# STM32N657 register map
File version: 1.0
CPU: CM55 r0p1, little endian, no MPU, FPU, vendor SysTick, 8 interrupt priority bits
Registers are 32-bit, read-write, reset 0x0 unless marked. A register's access mark holds for its fields unless they carry their own. Offsets are from the block's base; [hi:lo] are bit positions; {n}, {i} and the like mark numbered series; 'fields as' and 'values as' point back to an identical list.

## SYSCFG — System configuration controller
Base 0x46008000
Same registers: SYSCFG_S 0x56008000
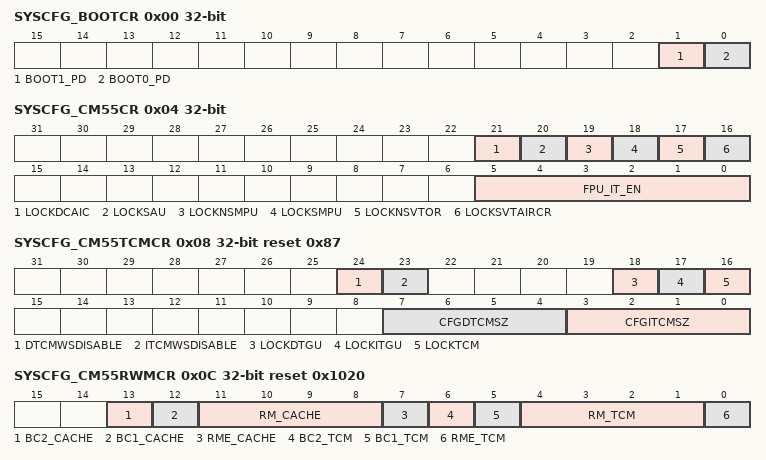
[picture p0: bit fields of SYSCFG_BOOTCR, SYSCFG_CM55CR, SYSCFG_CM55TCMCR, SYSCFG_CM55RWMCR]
0x00 SYSCFG_BOOTCR — SYSCFG boot pin control register
  [1] BOOT1_PD — BOOT1 pin pull-down disable
    0=Pull-down enabled. The BOOT1 pin can be left open and takes a value of 0 if open.; 1=Pull-down disabled. The BOOT1 pin must not be left open.
  [0] BOOT0_PD — BOOT0 pin pull-down disable
    0=Pull-down enabled. The BOOT0 pin can be left open and takes a value of 0 if open.; 1=Pull-down disabled. The BOOT0 pin must not be left open.
0x04 SYSCFG_CM55CR — SYSCFG Cortex-M55 control register
  [21] LOCKDCAIC — Disable access to the instruction cache direct cache access registers DCAICLR and DCAICRR.
  [20] LOCKSAU — Prevent changes to secure SAU memory regions already programmed.
  [19] LOCKNSMPU — Prevent changes to non-secure MPU memory regions already programmed.
  [18] LOCKSMPU — Prevent changes to programmed secure MPU memory regions.
  [17] LOCKNSVTOR — Prevent changes to the non-secure vector table base address.
  [16] LOCKSVTAIRCR — Prevent changes to:
  [5:0] FPU_IT_EN — Enable FPU exception
0x08 SYSCFG_CM55TCMCR reset 0x87 — SYSCFG Cortex-M55 TCM control register
  [24] DTCMWSDISABLE — Disable wait-state applied by default on extended DTCM memory.
  [23] ITCMWSDISABLE — Disable wait-state applied by default on extended ITCM memory.
  [18] LOCKDTGU — Disable writes to registers associated with the DTCM interface security gating.
  [17] LOCKITGU — Disable writes to registers associated with the ITCM interface security gating.
  [16] LOCKTCM — Disable writes to registers associated with the TCM region
  [7:4] CFGDTCMSZ — Select DTCM memory size
    8=128 Kbytes (default value); 9=256 Kbytes
  [3:0] CFGITCMSZ — Select ITCM memory size
    7=64 KB (default value); 8=128 Kbytes; 9=256 Kbytes
0x0C SYSCFG_CM55RWMCR reset 0x1020 — SYSCFG Cortex-CM55 memory RW margin register
  [13] BC2_CACHE — Biasing level adjust input recommended for Vnom + 10%
  [12] BC1_CACHE — Biasing level adjust input recommended for Vnom.
  [11:8] RM_CACHE — External read/write (RW) margin inputs for caches memories
  [7] RME_CACHE — RW margin enable input for caches memories
    0=Default RW margin settings; 1=Use external pin RW margin setting
  [6] BC2_TCM — Biasing level adjust input recommended for Vnom + 10%
  [5] BC1_TCM — Biasing level adjust input recommended for Vnom
  [4:1] RM_TCM — External RW margin inputs for TCM memories
  [0] RME_TCM — RW margin enable input for TCM memories
    values as RME_CACHE
0x10 SYSCFG_INITSVTORCR reset 0x18000000 — SYSCFG Cortex-M55 SVTOR control register
  [31:7] SVTOR_ADDR — Secure vector table base address
0x14 SYSCFG_INITNSVTORCR reset 0x8000000 — SYSCFG Cortex-M55 NSVTOR control register
  [31:7] NSVTOR_ADDR — Non-secure vector table base address
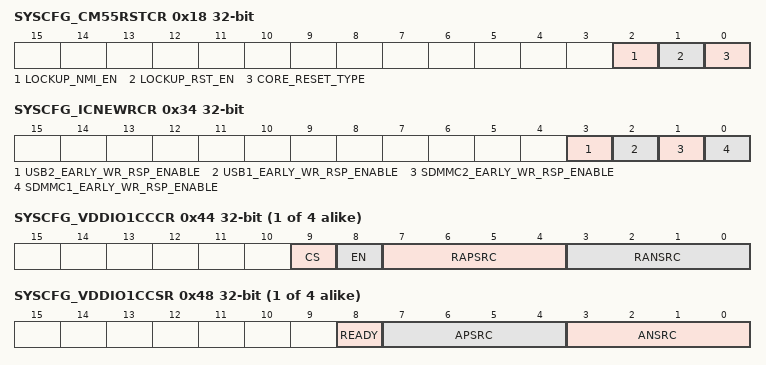
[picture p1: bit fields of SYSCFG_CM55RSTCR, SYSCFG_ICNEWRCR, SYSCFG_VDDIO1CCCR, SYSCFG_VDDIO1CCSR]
0x18 SYSCFG_CM55RSTCR — SYSCFG Cortex-M55 reset type control register
  [2] LOCKUP_NMI_EN — Select action to perform on a lockup state on the core
    0=Lockup state must be recovered from NVIC interrupt (default value); 1=Lockup generates a NMI on the core
  [1] LOCKUP_RST_EN — Select action to perform on a lockup state on the core
    0=Lockup state shall be recovered from interrupt (default value); 1=Lockup requests a warm reset to the RCC
  [0] CORE_RESET_TYPE — Select reset to apply on core upon SYSRESETREQ
    0=Warm reset (default value); 1=Power-on reset
0x1C SYSCFG_CM55PAHBWPR — SYSCFG Cortex-M55 P-AHB write posting control register
  [0] PAHB_ERROR_ACK — Error capture in write posting buffer
    0=Error capture; 1=Clean error
0x20 SYSCFG_VENCRAMCR — SYSCFG VENCRAM control register
  [0] VENCRAM_EN — VENCRAM allocation VENC if active, or to system (if VENC inactive)
    0=VENCRAM reserved for the VENC; 1=VENCRAM available for the system (VENC inactive)
0x24 SYSCFG_POTTAMPRSTCR — SYSCFG potential tamper reset register
  [0] POTTAMPERSETMASK — This bit can be set by software to mask PKA, SAES, CRYP1/2, and HASH reset, in case of potential tamper.
    0=PKA, SAES, CRYP1/2, and HASH reset in case of potential tamper; 1=PKA, SAES, CRYP1/2, and HASH not reset in case of potential tamper
0x34 SYSCFG_ICNEWRCR — SYSCFG AHB-AXI bridge early write response control register
  [all] fields
    0=Early-write response disabled. The last AHB write data beat receives the AXI buffered response for the complete AHB transaction.; 1=Early-write response enabled. AHB-Lite write data beats receive an automatic OK response from the AHB-to-AXI bridge, whatever the B-channel AXI response.
  [3] USB2_EARLY_WR_RSP_ENABLE
  [2] USB1_EARLY_WR_RSP_ENABLE
  [1] SDMMC2_EARLY_WR_RSP_ENABLE
  [0] SDMMC1_EARLY_WR_RSP_ENABLE
0x38 SYSCFG_ICNCGCR — SYSCFG ICN clock gating control register
  [31:0] ICNCGCR — When bit[i] is set to 1, ICN clock gating[i] is OFF.
0x3C SYSCFG_ICNBWRCR — SYSCFG ICN bandwidth regulator control register
  [31:0] ICNBWRCR — Bandwidth regulator control bits
0x40 SYSCFG_IOCR — SYSCFG /O control register
  [31:0] IOCR — Digital or analog pins
    0=High-speed mode disabled, or use ADC ANA pin; 1=High-speed mode enabled, or connect internal ADC ANA signal to GPIO
{0x3C+8i} SYSCFG_VDDIO{i}CCCR (i=1..4) — SYSCFG VDDIO{i} compensation cell control register
  [9] CS — Selects the code to be applied for the compensation cell of I/Os supplied by VDDIOx.
    0=VDDIOx I/O code from the cell (available in the SYSCFG_VDDIOxCCSR); 1=VDDIOx I/O code from RANSRC[3:0] and RAPSRC[3:0] in this register
  [8] EN — Enables the compensation cell of I/Os supplied by VDDIOx.
    0=VDDIOx I/O compensation cell disabled; 1=VDDIOx I/O compensation cell enabled
  [7:4] RAPSRC — These bits are written by software to define an I/O compensation code for PMOS transistors. This code is applied to the I/O compensation cell when CS = 1.
  [3:0] RANSRC — These bits are written by software to define an I/O compensation code for NMOS transistors. This code is applied to the I/O compensation cell when the CS = 1.
{0x40+8i} SYSCFG_VDDIO{i}CCSR ro (i=1..4) — SYSCFG VDDIO{i} compensation cell status register
  [8] READY — Provides the compensation cell status of I/Os supplied by VDDIOx
    0=VDDIOx I/O compensation cell not ready; 1=VDDIOx I/O compensation cell ready
  [7:4] APSRC — This value is provided by the cell, and can be used by the CPU to compute an I/O compensation cell code for PMOS transistors.
  [3:0] ANSRC — This value is provided by the cell, and can be used by the CPU to compute an I/O compensation cell code for NMOS transistors.
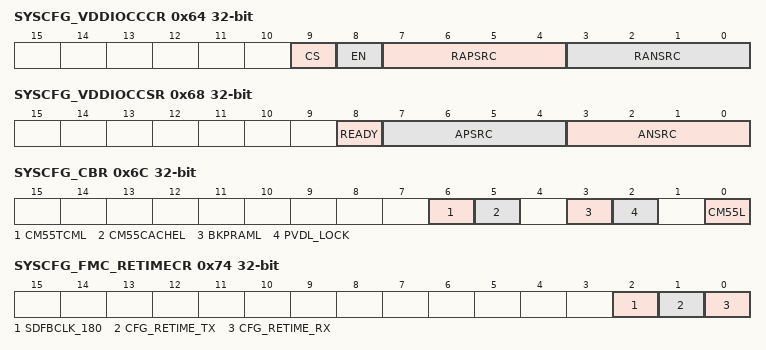
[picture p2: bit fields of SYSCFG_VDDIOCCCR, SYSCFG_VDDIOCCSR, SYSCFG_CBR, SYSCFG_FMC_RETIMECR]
0x64 SYSCFG_VDDIOCCCR — SYSCFG VDDIO compensation cell control register
  [9] CS — Selects the code to be applied for the compensation cell of I/Os supplied by VDDIO.
    0=VDDIO I/O code from the cell (available in the SYSCFG_VDDIOCCSR); 1=VDDIO I/O code from RANSRC[3:0] and RAPSRC[3:0]
  [8] EN — Enables the compensation cell of I/Os supplied by VDDIO.
    0=VDDIO I/O compensation cell disabled; 1=VDDIO I/O compensation cell enabled
  [7:4] RAPSRC — These bits are written by software to define an I/O compensation code for PMOS transistors. This code is applied to the I/O compensation cell when CS = 1.
  [3:0] RANSRC — These bits are written by software to define an I/O compensation code for NMOS transistors. This code is applied to the I/O compensation cell when CS = 1.
0x68 SYSCFG_VDDIOCCSR ro — SYSCFG VDDIO compensation cell status register
  [8] READY — Provides the compensation cell status of I/Os supplied by VDDIO
    0=VDDIO I/O compensation cell not ready; 1=VDDIO I/O compensation cell ready
  [7:4] APSRC — This value is provided by the cell, and can be used by the CPU to compute an I/O compensation cell code for PMOS transistors.
  [3:0] ANSRC — This value is provided by the cell, and can be used by the CPU to compute an I/O compensation cell code for NMOS transistors.
0x6C SYSCFG_CBR — SYSCFG control timer break register
  [6] CM55TCML — CM55 TCM double ECC error lock
    0=Cortex-M55 TCM double ECC error signal disconnected from TIM1/8/15/16/17 break inputs; 1=Cortex-M55 TCM double ECC error signal connected to TIM1/8/15/16/17 break inputs
  [5] CM55CACHEL — CM55 cache double ECC error lock
    0=Cortex-M55 cache double ECC error signal disconnected from TIM1/8/15/16/17 break inputs; 1=Cortex-M55 cache double ECC error signal connected to TIM1/8/15/16/17 break inputs
  [3] BKPRAML — Backup SRAM double ECC error lock
    0=Backup SRAM double ECC error signal disconnected from TIM1/8/15/16/17 break inputs; 1=Backup SRAM double ECC error signal connected to TIM1/8/15/16/17 break inputs
  [2] PVDL_LOCK — PVD lock enable
    0=PVD interrupt disconnected from TIM1/8/15/16/17 break input. PVDE bits can be programmed by the application.; 1=PVD interrupt connected to TIM1/8/15/16/17 break input. PVDE and bits are read only.
  [0] CM55L — CM55 lockup lock enable
    0=Cortex-M55 lockup output disconnected from TIM1/8/15/16/17 break inputs; 1=Cortex-M55 lockup output disconnected from TIM1/8/15/16/17 break inputs
0x70 SYSCFG_SEC_AIDCR reset 0x1 — SYSCFG DMA CID secure control register
  [2:0] DMACID_SEC — Secure OS allocates specific CID to DMA channel through these bits.
0x74 SYSCFG_FMC_RETIMECR — SYSCFG FMC retiming logic control register
  [2] SDFBCLK_180 — Delay on feedback clock
    0=No delay on the feedback clock; 1=Half a cycle delay on the feedback clock
  [1] CFG_RETIME_TX — Retiming on Tx path
    0=No retiming on Tx path; 1=Retiming on Tx path
  [0] CFG_RETIME_RX — Retiming on Rx path
    0=No retiming on Rx path; 1=Retiming on Rx path
0x78 SYSCFG_NPU_ICNCR — SYSCFG NPU RAM interleaving control register
  [0] INTERLEAVING_ACTIVE — Control interleaving on NPU RAMs
    0=Interleaving disabled; 1=Interleaving enabled
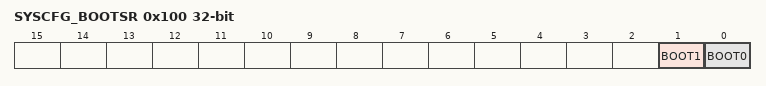
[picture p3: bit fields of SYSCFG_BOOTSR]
0x100 SYSCFG_BOOTSR ro — SYSCFG boot pin status register
  [1] BOOT1 — BOOT1 pin value
    0=BOOT1 pin connected to VSS (or left open if BOOT1_PD = 0 in SYSCFG_BOOTCR); 1=BOOT1 pin connected to VDD
  [0] BOOT0 — BOOT0 pin value
    0=BOOT0 pin connected to VSS (or left open if BOOT0_PD = 0); 1=BOOT0 pin connected to VDD
0x104 SYSCFG_AHBWP_ERROR_SR ro — SYSCFG AHB write posting address error register
  [31:0] PAHB_ERROR_ADDR — Reports address of the first error in P-AHB write-posting buffer
0x400 SYSCFG_SMPSHDPCR — SYSCFG SMPS observable signals through HDP selection configuration register
  [3:0] SMPSHDPSEL — Others: Reserved
    0=Standard run mode (no HDP); 12=Analyze fsm mode analysis; 13=Analyze fsm mos analysis; 14=Analyze fsm rampe analysis; 15=Analyze fsm mode analysis
0x800 SYSCFG_NONSEC_AIDCR reset 0x1 — SYSCFG DMA CID non-secure control register
  [2:0] DMACID_NONSEC — Non-secure OS allocates specific CID to DMA channel through these bits
